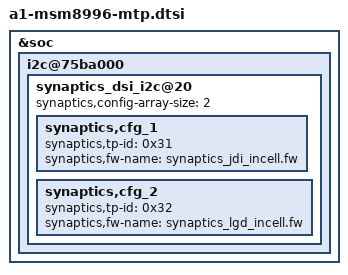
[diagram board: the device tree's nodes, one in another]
/* Copyright (c) 2015, The Linux Foundation. All rights reserved.
 * Copyright (C) 2016 XiaoMi, Inc.
 *
 * This program is free software; you can redistribute it and/or modify
 * it under the terms of the GNU General Public License version 2 and
 * only version 2 as published by the Free Software Foundation.
 *
 * This program is distributed in the hope that it will be useful,
 * but WITHOUT ANY WARRANTY; without even the implied warranty of
 * MERCHANTABILITY or FITNESS FOR A PARTICULAR PURPOSE.  See the
 * GNU General Public License for more details.
 */

#include "msm8996-gemini-common.dtsi"

&soc {
	i2c@75ba000 {
		synaptics_dsi_i2c@20 {
			synaptics,config-array-size = <2>;
			synaptics,cfg_1 {
				synaptics,tp-id = /bits/ 8 <0x31>;
				synaptics,fw-name = "synaptics_jdi_incell.fw";
			};
			synaptics,cfg_2 {
				synaptics,tp-id = /bits/ 8 <0x32>;
				synaptics,fw-name = "synaptics_lgd_incell.fw";
			};
		};
	};
};
